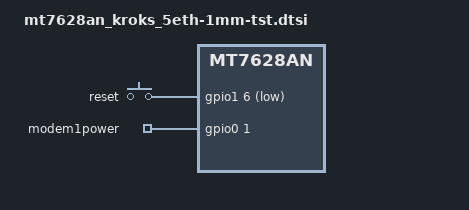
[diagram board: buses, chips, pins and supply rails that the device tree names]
/dts-v1/;

#include "mt7628an_kroks.dtsi"
#include "mt7628an_kroks_16m.dtsi"

#include <dt-bindings/input/input.h>
#include <dt-bindings/gpio/gpio.h>

/ {
	keys {
		compatible = "gpio-keys";

		reset {
			label = "reset";
			gpios = <&gpio1 6 GPIO_ACTIVE_LOW>;
			linux,code = <KEY_RESTART>;
		};
	};

	gpio_export {
		compatible = "gpio-export";
		#size-cells = <0>;

		modem1power {
			gpio-export,name = "modem1power";
			gpio-export,output = <1>;
			gpios = <&gpio0 1 GPIO_ACTIVE_HIGH>;
		};
	};
};

&esw {
	mediatek,portmap = <0x3e>;
};

&state_default {
	gpio {
		ralink,group = "i2s", "wdt", "p4led_an", "p3led_an", "p2led_an", "p1led_an", "p0led_an", "wled_an";
		ralink,function = "gpio";
	};
};
